# SPC1068 register map
File version: 20180100_70611510
CPU: CM3 r2p1, little endian, MPU, no FPU, 4 interrupt priority bits
Registers are 32-bit, read-write, reset 0x0 unless marked. A register's access mark holds for its fields unless they carry their own. Offsets are from the block's base; [hi:lo] are bit positions; {n}, {i} and the like mark numbered series; 'fields as' and 'values as' point back to an identical list; <NAME> marks a mode.

## SSP — NOEN
Base 0x40005000
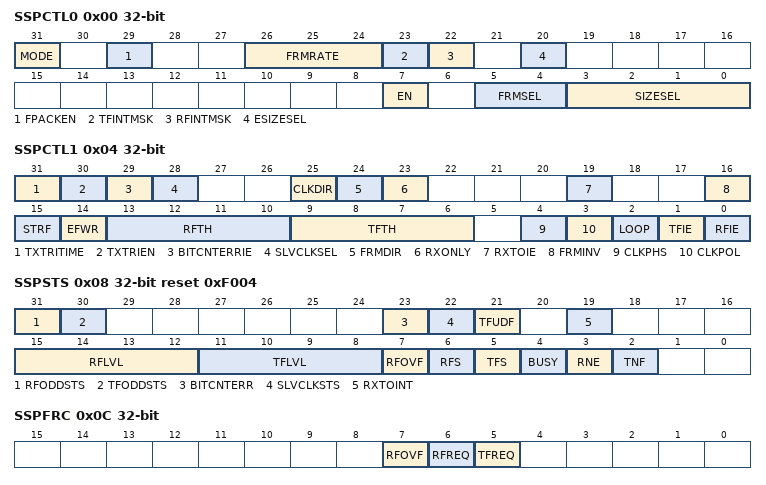
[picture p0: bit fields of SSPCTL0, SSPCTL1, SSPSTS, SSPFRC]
0x00 SSPCTL0 — SSP Control Register 0
  [31] MODE
    0=SPI (Normal SSP mode); 1=SPI_NETWORK (Network mode)
  [29] FPACKEN — FIFO Packing Enable
    0=FIFO_PACK_DISABLE (FIFO packing mode disabled); 1=FIFO_PACK_ENABLE (FIFO packing mode enabled)
  [26:24] FRMRATE — Frame Rate Divider Control. Value of 0x0-0x7 specifies the number of time slots per frame when in network mode (the actual number of time slots is this field +1, so 1 to 8 time slots can be specified).
    {v}={v+1}_SLOT_PER_FRAME (v=0..7)
  [23] TFINTMSK — Transmit FIFO Underflow Interrupt Mask
    0=TXFIFO_UNDERFLOW_INT_UNMASK (TFUDF events generate an SSP interrupt); 1=TXFIFO_UNDERFLOW_INT_MASK (TFUDF events do NOT generate an SSP interrupt)
  [22] RFINTMSK — Receive FIFO Overflow Interrupt Mask
    0=RXFIFO_OVERFLOW_INT_UNMASK (RFOVF events generate an SSP interrupt); 1=RXFIFO_OVERFLOW_INT_MASK (RFOVF events do NOT generate an SSP interrupt)
  [20] ESIZESEL — Extended Data Size Select
    0=DISABLE (A 0 is pre-appended to the SIZESEL value to set the SIZESEL range from 1 to 16 bits); 1=ENABLE (A 1 is pre-appended to the SIZESEL value to set the SIZESEL range from 17 to 32 bits)
  [7] EN — Synchronous Serial Port Enable
    0=DISABLE (SSP port is disabled); 1=ENABLE (SSP port is enabled)
  [5:4] FRMSEL — Frame Format. This field must be written with 0x3 = to select the PSP format.
    0=SPI_MOTOROLA (Motorola Serial Peripheral Interface (SPI)); 1=SSP_TI (Texas Instruments Synchronous Serial Protocol (SSP)); 3=PSP (Programmable Serial Protocol (PSP))
  [3:0] SIZESEL — Data Size Select. ESIZESEL SIZESEL Data Size. 1 0000 17-bit data. 1 0001 18-bit data. 1 0010 19-bit data. 1 0011 20-bit data. 1 0100 21-bit data. 1 0101 22-bit data. 1 0110 23-bit data. 1 0111 24-bit data. 1 1000 25-bit data. 1 1001 26-bit data. 1 1010 27-bit data. 1 1011 28-bit data. 1 1100 29-bit data. 1 1101 30-bit data. 1 1110 31-bit data. 1 1111 32-bit data. ESIZESEL SIZESEL Data Size. 0 0000 1-bit data. 0 0001 2-bit data. 0 0010 3-bit data. 0 0011 4-bit data. 0 0100 5-bit data. 0 0101 6-bit data. 0 0110 7-bit data. 0 0111 8-bit data. 0 1000 9-bit data. 0 1001 10-bit data. 0 1010 11-bit data. 0 1011 12-bit data. 0 1100 13-bit data. 0 1101 14-bit data. 0 1110 15-bit data. 0 1111 16-bit data
    {v}=FRAME_{v+1}_OR_{v+17}BIT (v=0..15)
0x04 SSPCTL1 — SSP Control Register 1
  [31] TXTRITIME — TXD Tri-stated Enable On Last Phase
    0=TX_TRISTATE_MODE_0 (SSP_TXD is tri-stated 1/2 clock cycle after the beginning of the LSB); 1=TX_TRISTATE_MODE_1 (SSP_TXD output signal is tri-stated on the clock edge that ends the LSB)
  [30] TXTRIEN — TXD Tri-Stated Enable
    0=TX_TRISTATE_DISABLE (SSP_TXD output signal is not tri-stated); 1=TX_TRISTATE_ENALBLE (SSP_TXD is tri-stated when not transmitting data)
  [29] BITCNTERRIE — Enable Bit Count Error Interrupt
    0=BCE_INT_DISABLE (Interrupt due to a bit count error is disabled); 1=BCE_INT_ENABLE (Interrupt due to a bit count error is enabled)
  [28] SLVCLKSEL — Slave Clock Free Running
    0=SLAVE_INTERNAL_SCLK (Clock input to SSP_CLK is not active when SSPCTL1_CLKDIR is set to 1); 1=SLAVE_EXTENAL_SCLK (Clock input to SSP_CLK is active when SSPCTL1_CLKDIR is set to 1)
  [25] CLKDIR — SSP Serial Bit Rate Clock (SSP_CLK) Direction
    0=MASTER_MODE (Master mode, SSP port drives SSP_CLK); 1=SLAVE_MODE (Slave mode, SSP port receives SSP_CLK)
  [24] FRMDIR — SSP Frame (SSP_FRM) Direction
    0=MASTER_MODE (Master mode, SSP port drives SSP_FRM); 1=SLAVE_MODE (Slave mode, SSP port receives SSP_FRM)
  [23] RXONLY — Receive Without Transmit
    0=TXRX_MODE (Transmit/Receive mode); 1=RX_MODE (Receive without Transmit mode)
  [19] RXTOIE — Receiver Time-out Interrupt Enable
    0=RX_TIMEOUT_INT_DISABLE (Receiver time-out interrupt is disabled); 1=RX_TIMEOUT_INT_ENABLE (Receiver time-out interrupt is enabled)
  [16] FRMINV — Invert Frame Signal
    0=FRM_NOT_INVERT (SSP_FRM polarity is determined by the PSP polarity bits); 1=FRM_INVERT (SSP_FRM is inverted from normal-SSP_FRM (as defined by the PSP polarity bits). (Works in all frame formats: SPI, SSP, and PSP))
  [15] STRF — Select FIFO For EFWR. Select FIFO For EFWR (Test Mode Bit). Only when EFWR = 1.
    0=SEL_TXFIFO (TXFIFO is selected for both writes and reads through the SSP Data Register); 1=SEL_RXFIFO (RXFIFO is selected for both writes and reads through the SSP Data Register)
  [14] EFWR — Enable FIFO Write/read. Enable FIFO Write/read (Test Mode Bit)
    0=FIFO_TEST_DISABLED (FIFO write/read special function is disabled (normal SSP operational mode)); 1=FIFO_TEST_ENABLED (FIFO write/read special function is enabled)
  [13:10] RFTH — RXFIFO Trigger Threshold. Sets threshold level at which RXFIFO asserts interrupt. Level should be set to the preferred threshold value minus 1.
  [9:6] TFTH — TXFIFO Trigger Threshold. Sets threshold level at which TXFIFO asserts interrupt. Level should be set to the preferred threshold value minus 1.
  [4] CLKPHS — Motorola SPI SSP_CLK phase setting
    0=SAMPLE_ON_1st_CLK_EDGE (SSP_CLK is inactive until one cycle after the start of a frame and active until 1/2 cycle before the end of a frame); 1=SAMPLE_ON_2nd_CLK_EDGE (SSP_CLK is inactive until 1/2 cycle after the start of a frame and active until one cycle)
  [3] CLKPOL — Motorola SPI SSP_CLK Polarity Setting
    0=CLK_IDLE_LOW (The inactive or idle state of SSP_CLK is low); 1=CLK_IDLE_HIGH (The inactive or idle state of SSP_CLK is high)
  [2] LOOP — Loopback Mode. Loopback Mode (Test Mode Bit)
    0=DISABLE (Normal serial port operation is enabled); 1=ENABLE (Output of TX serial shifter is internally connected to input of RX serial shifter)
  [1] TFIE — Transmit FIFO Interrupt Enable
    0=TXFIFO_INT_DISABLE (TXFIFO threshold-level-reached interrupt is disabled); 1=TXFIFO_INT_ENABLE (TXFIFO threshold-level-reached interrupt is enabled)
  [0] RFIE — Receive FIFO Interrupt Enable
    0=RXFIFO_INT_DISABLE (RXFIFO threshold-level-reached interrupt is disabled); 1=RXFIFO_INT_ENABLE (RXFIFO threshold-level-reached interrupt is enabled)
0x08 SSPSTS reset 0xF004 — SSP Status Register
  [31] RFODDSTS ro — RX FIFO Odd Sample Status. Note: that this bit needs to be looked at only when FIFO Packing is enabled (<FIFO Packing Enable> field in SSP Control Register 0 is set). Otherwise this bit is zero. When SSP port is in Packed mode, and the CPU is used to read the RXFIFO, CPU should make sure that <Receive FIFO Not Empty>=1 AND this field=0 before it attempts to read the RXFIFO.
    0=2_SAMPLE_IN_RXFIFO (RXFIFO entry has 2 samples); 1=1_SAMPLE_IN_RXFIFO (RXFIFO entry has 1 sample)
  [30] TFODDSTS ro — TX FIFO Odd Sample Status. When SSP port is in packed mode, the number of samples in the TX FIFO is: (<Transmit FIFO Level>*2 + this field), when <Transmit FIFO Not Full>=1; 32, when <Transmit FIFO Not Full>=0. . The TX FIFO cannot accept new data when <Transmit FIFO Not Full>=1 and <Transmit FIFO Level>=15 and this field=1. (The TX FIFO has 31 samples). . Note: that this bit needs to be read only when FIFO Packing is enabled (<FIFO Packing Enable> in the SSP Control Register 0 set). Otherwise this bit is zero.
    0=EVEN_SAMPLE_IN_TXFIFO (TXFIFO entry has an even number of samples); 1=ODD_SAMPLE_IN_TXFIFO (TXFIFO entry has an even number of samples)
  [23] BITCNTERR — Bit Count Error
    0=BCE_NOT_OCCUR (The SSP port has not experienced a bit count error); 1=BCE_OCCUR (The SSP_FRM signal was asserted when the bit counter was not zero)
  [22] SLVCLKSTS ro — Slave Clock Status
    0=SLAVE_PORT_READY (The SSP port is ready for slave clock operations); 1=SLAVE_PORT_BUSY (The SSP port is currently busy synchronizing slave mode signals)
  [21] TFUDF — Transmit FIFO Underflow
    0=TXFIFO_UNDERFLOW_NOT_OCCUR (The TXFIFO has not experienced an underflow); 1=TXFIFO_UNDERFLOW_OCCUR (A read from the TXFIFO was attempted when the TXFIFO was empty, causes an interrupt if it is enabled (<Transmit FIFO Underrun Interrupt Mask> in the SSP Control Register 0 is 0).)
  [19] RXTOINT — Receiver Time-out Interrupt
    0=RX_TIMEOUT_NOT_OCCUR (No receiver time-out is pending); 1=RX_TIMEOUT_OCCUR (Receiver time-out pending, causes an interrupt request)
  [15:12] RFLVL ro — Receive FIFO Level. Number of entries minus one in RXFIFO. . Note: When the value 0xF is read, the RXFIFO is either empty or full, and software should read the <Receive FIFO Not Empty> field.
  [11:8] TFLVL ro — Transmit FIFO Level. Number of entries in TXFIFO. . Note: When the value 0x0 is read, the TXFIFO is either empty or full, and software should read the <Transmit FIFO Not Full> field.
  [7] RFOVF — Receive FIFO Overflow
    0=RXFIFO_OVERFLOW_NOT_OCCUR (Receive FIFO Overflow); 1=RXFIFO_OVERFLOW_OCCUR (Attempted data write to full RXFIFO, causes an interrupt request)
  [6] RFS ro — Receive FIFO Service Request
    0=RXFIFO_EVENT_NOT_OCCUR (RXFIFO level is at or below RFT threshold (RFT), or SSP port is disabled); 1=RXFIFO_EVENT_OCCUR (RXFIFO level exceeds RFT threshold (RFT), causes an interrupt request)
  [5] TFS ro — Transmit FIFO Service Request
    0=TXFIFO_EVENT_NOT_OCCUR (TXFIFO level exceeds the TFT threshold (TFT + 1), or SSP port disabled); 1=TXFIFO_EVENT_OCCUR (TXFIFO level is at or below TFT threshold (TFT + 1), causes an interrupt request)
  [4] BUSY ro — SSP Busy
    0=PORT_IDLE (SSP port is idle or disabled); 1=PORT_BUSY (SSP port is currently transmitting or receiving framed data)
  [3] RNE ro — Receive FIFO Not Empty
    0=RXFIFO_EMPTY (RXFIFO is empty); 1=RXFIFO_NOT_EMPYT (RXFIFO is not empty)
  [2] TNF ro — Transmit FIFO Not Full
    0=TXFIFO_FULL (TXFIFO is full); 1=TXFIFO_NOT_FULL (TXFIFO is not full)
0x0C SSPFRC — SSP Interrupt Test Register
  [7] RFOVF — Test RXFIFO Overrun
    0=NO_EFFECT (No RXFIFO overflow service request); 1=FORCE_RX_OVERFLOW_EVENT (Generates a non-maskable RXFIFO overflow interrupt request)
  [6] RFREQ — Test RXFIFO Service Request
    0=NO_EFFECT (No RXFIFO-service request); 1=FORCE_RXFIFO_REQUEST_EVENT (Generates a non-maskable RXFIFO-service interrupt request)
  [5] TFREQ — Test TXFIFO Service Request
    0=NO_EFFECT (No TXFIFO-service request); 1=FORCE_TXFIFO_REQUEST_EVENT (Generates a non-maskable TXFIFO-service interrupt request)
0x10 SSPDATA
  [31:0] VAL — DATA value. Data to be written to the TXFIFO or read from the RXFIFO
0x28 SSPTO — SSP Time Out Register
  [23:0] VAL — Timeout Value. Define the time-out interval by 2^VAL-1.
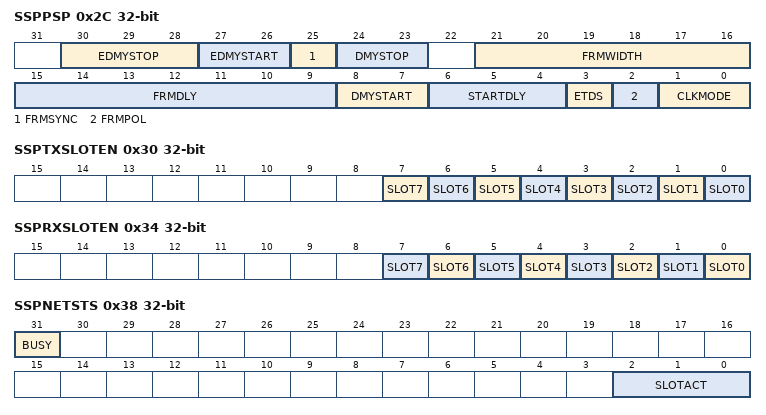
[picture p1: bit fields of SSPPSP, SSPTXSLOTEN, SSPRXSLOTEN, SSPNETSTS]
0x2C SSPPSP — SSP Programmable Serial Protocol Register
  [30:28] EDMYSTOP — Extended Dummy Stop. The most-significant bits of the dummy stop delay. Note: Do not use in PSP Network mode.
    {v}=EXTENDED_DUMMY_STOP_LEN_{v} (EXTENDED DUMMY STOP {v}) (v=0..7)
  [27:26] EDMYSTART — Extended Dummy Start. The most-significant bits of the dummy start delay. Note: Do not use in PSP Network mode.
    {v}=EXTENDED_DUMMY_START_LEN_{v} (EXTENDED DUMMY START {v}) (v=0..3)
  [25] FRMSYNC — Frame Sync Relative Timing Bit
    0=FRAME_INTERVAL_DMYSTOP (Next frame is asserted after the end of the DMYSTOP timing); 1=FRAME_NO_INTERVAL_DMYSTOP (Next frame is asserted with the LSB of the previous frame)
  [24:23] DMYSTOP — Dummy Stop. The least-significant bits of the dummy stop delay Programmed value of <Extended Dummy Stop> + this field specifies the number (0-31) of active clocks (SSP_CLK) that follow the end of the transmitted data. Note: Do not use in PSP Network mode.
    {v}=DUMMY_STOP_LEN_{v} (Dummy Stop length {v}) (v=0..3)
  [21:16] FRMWIDTH — Serial Frame Width. Least-significant bits of the serial frame width Programmed value of this field specifies the frame width from 0x00 (one SSP_CLK cycle) to 0x3F (63 SSP_CLK cycles).
  [15:9] FRMDLY — Serial Frame Delay. Programmed value specifies the number (0 -127) of active one-half clocks (SSP_CLK) asserted from the mostsignificant bit of SSP_TXD (output) or SSP_RXD (input) being driven to SSP_FRM. Note: Do not use in PSP Network mode.
  [8:7] DMYSTART — Dummy Start. Least-significant bits of the dummy start delay. Programmed value of this field specifies the number (0-15) of active clocks (SSP_CLKs) between the end of start delay and when the most-significant bit of transmit/receive data is driven. Note: Do not use in PSP Network mode.
    {v}=DUMMY_START_DELAY_LEN_{v} (Dummy start by {v} clock) (v=0..3)
  [6:4] STARTDLY — Start Delay. Programmed value specifies the number (0-7) of non-active clocks (SSP_CLK) that define the duration of idle time. Note: Do not use in PSP Network mode.
    {v}=START_DELAY_LEN_{v} (Start Delay by {v} clock) (v=0..7)
  [3] ETDS — End Of Transfer Data State
    0=TRANSFER_NOT_END (Transfer pending); 1=TRANSFER_END (Transfer ended)
  [2] FRMPOL — Serial Frame Polarity
    0=FRM_ACTIVE_LOW (SSP_FRM is active low (0b0)); 1=FRM_ACTIVE_HIGH (SSP_FRM is active high (0b1))
  [1:0] CLKMODE — Serial Bit-rate Clock Mode
    0=BIT_RATE_CLK_MODE_0 (Data Driven (Falling), Data Sampled (Rising), Idle State (Low)); 1=BIT_RATE_CLK_MODE_1 (Data Driven (Rising), Data Sampled (Falling), Idle State (Low)); 2=BIT_RATE_CLK_MODE_2 (Data Driven (Rising), Data Sampled (Falling), Idle State (High)); 3=BIT_RATE_CLK_MODE_3 (Data Driven (Falling), Data Sampled (Rising), Idle State (High))
0x30 SSPTXSLOTEN — SSP TX Time Slot Active Register
  [7] SLOT7 — Tx Time Slot 7 Active
    0=TX_DISABLE (SSP port does NOT transmit data in this time slot); 1=TX_ENABLE (SSP port does NOT transmit data in this time slot)
  [6] SLOT6 — Tx Time Slot 6 Active
    0=TX_DISABLE (SSP port does transmit data in this time slot); 1=TX_ENABLE (SSP port does NOT transmit data in this time slot)
  [5] SLOT5 — Tx Time Slot 5 Active
    values as SLOT7
  [4] SLOT4 — Tx Time Slot 4 Active
    0=TX_DISABLE (SSP port does NOT transmit data in this time slot); 1=TX_ENABLE (SSP port does transmit data in this time slot)
  [3] SLOT3 — Tx Time Slot 3 Active
    values as SLOT7
  [2] SLOT2 — Tx Time Slot 2 Active
    values as SLOT6
  [1] SLOT1 — Tx Time Slot 1 Active
    values as SLOT7
  [0] SLOT0 — Tx Time Slot 0 Active
    values as SLOT4
0x34 SSPRXSLOTEN — SSP RX Time Slot Active Register
  [all] fields
    0=RX_DISABLE (SSP port does not receive data in this time slot); 1=RX_ENABLE (SSP port receives data in this time slot)
  [n] SLOT{n} (n=0..7) — Rx Time Slot {n} Active
0x38 SSPNETSTS ro — SSP Time Slot Status Register
  [31] BUSY — Network Mode Busy
    0=NETWORK_IDLE (SSP port is in network mode and no frame is currently active); 1=NETWORK_BUSY (SSP port is in network mode and a frame is currently active)
  [2:0] SLOTACT — Time Slot Status. Value indicates which time slot is currently active. Because of synchronization between the SSP port's SSP_CLK domain and an internal bus clock domain, the value in this field becomes stable between the beginning and end of the currently active time slot.
    0=1_ACTIVE_SLOT; {v}={v+1}_ACTIVE_SLOT ({v+1} Active slots) (v=1..7)
